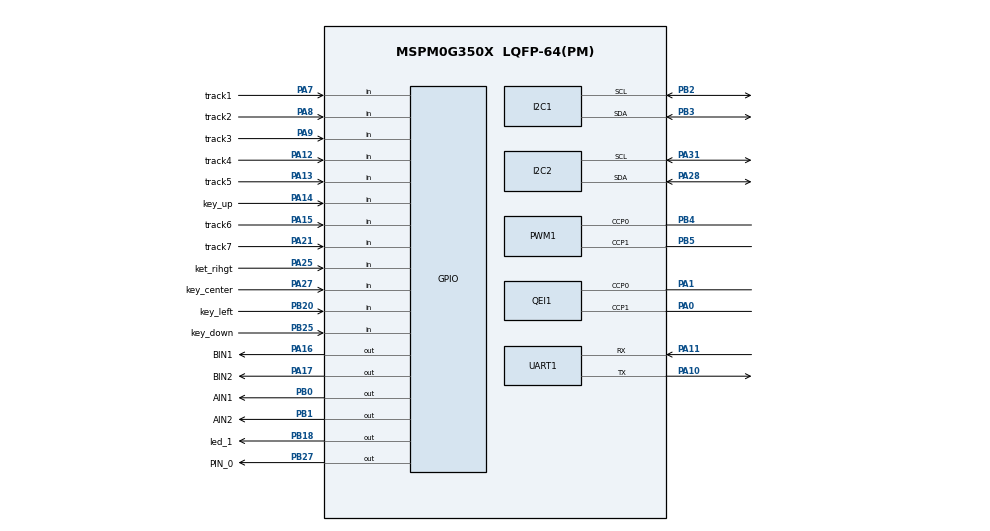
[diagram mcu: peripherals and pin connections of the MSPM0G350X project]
/**
 * @cliArgs --device "MSPM0G350X" --part "Default" --package "LQFP-64(PM)" --product "mspm0_sdk@2.04.00.06"
 * @versions {"tool":"1.23.1+4034"}
 */

/**
 * Import the modules used in this configuration.
 */
const GPIO    = scripting.addModule("/ti/driverlib/GPIO", {}, false);
const GPIO1   = GPIO.addInstance();
const GPIO2   = GPIO.addInstance();
const GPIO3   = GPIO.addInstance();
const GPIO4   = GPIO.addInstance();
const GPIO5   = GPIO.addInstance();
const I2C     = scripting.addModule("/ti/driverlib/I2C", {}, false);
const I2C1    = I2C.addInstance();
const I2C2    = I2C.addInstance();
const PWM     = scripting.addModule("/ti/driverlib/PWM", {}, false);
const PWM1    = PWM.addInstance();
const QEI     = scripting.addModule("/ti/driverlib/QEI", {}, false);
const QEI1    = QEI.addInstance();
const SYSCTL  = scripting.addModule("/ti/driverlib/SYSCTL");
const SYSTICK = scripting.addModule("/ti/driverlib/SYSTICK");
const TIMER   = scripting.addModule("/ti/driverlib/TIMER", {}, false);
const TIMER1  = TIMER.addInstance();
const TIMER2  = TIMER.addInstance();
const TIMER3  = TIMER.addInstance();
const UART    = scripting.addModule("/ti/driverlib/UART", {}, false);
const UART1   = UART.addInstance();

/**
 * Write custom configuration values to the imported modules.
 */
const divider9       = system.clockTree["UDIV"];
divider9.divideValue = 2;

const gate7  = system.clockTree["MFCLKGATE"];
gate7.enable = true;

const multiplier2         = system.clockTree["PLL_QDIV"];
multiplier2.multiplyValue = 4;

const mux4       = system.clockTree["EXHFMUX"];
mux4.inputSelect = "EXHFMUX_XTAL";

const mux8       = system.clockTree["HSCLKMUX"];
mux8.inputSelect = "HSCLKMUX_SYSPLL0";

const mux12       = system.clockTree["SYSPLLMUX"];
mux12.inputSelect = "zSYSPLLMUX_HFCLK";

const pinFunction4        = system.clockTree["HFXT"];
pinFunction4.enable       = true;
pinFunction4.inputFreq    = 40;
pinFunction4.HFXTStartup  = 10;
pinFunction4.HFCLKMonitor = true;

GPIO1.$name                              = "key_gpio";
GPIO1.associatedPins.create(5);
GPIO1.associatedPins[0].direction        = "INPUT";
GPIO1.associatedPins[0].internalResistor = "PULL_DOWN";
GPIO1.associatedPins[0].assignedPort     = "PORTA";
GPIO1.associatedPins[0].$name            = "key_center";
GPIO1.associatedPins[0].assignedPin      = "27";
GPIO1.associatedPins[0].pin.$assign      = "PA27";
GPIO1.associatedPins[1].$name            = "ket_rihgt";
GPIO1.associatedPins[1].direction        = "INPUT";
GPIO1.associatedPins[1].internalResistor = "PULL_DOWN";
GPIO1.associatedPins[1].assignedPort     = "PORTA";
GPIO1.associatedPins[1].assignedPin      = "25";
GPIO1.associatedPins[1].pin.$assign      = "PA25";
GPIO1.associatedPins[2].$name            = "key_left";
GPIO1.associatedPins[2].direction        = "INPUT";
GPIO1.associatedPins[2].internalResistor = "PULL_DOWN";
GPIO1.associatedPins[2].assignedPort     = "PORTB";
GPIO1.associatedPins[2].assignedPin      = "20";
GPIO1.associatedPins[2].pin.$assign      = "PB20";
GPIO1.associatedPins[3].$name            = "key_up";
GPIO1.associatedPins[3].direction        = "INPUT";
GPIO1.associatedPins[3].internalResistor = "PULL_DOWN";
GPIO1.associatedPins[3].assignedPort     = "PORTA";
GPIO1.associatedPins[3].assignedPin      = "14";
GPIO1.associatedPins[3].pin.$assign      = "PA14";
GPIO1.associatedPins[4].$name            = "key_down";
GPIO1.associatedPins[4].direction        = "INPUT";
GPIO1.associatedPins[4].assignedPort     = "PORTB";
GPIO1.associatedPins[4].assignedPin      = "25";
GPIO1.associatedPins[4].internalResistor = "PULL_DOWN";
GPIO1.associatedPins[4].pin.$assign      = "PB25";

const Board = scripting.addModule("/ti/driverlib/Board", {}, false);

GPIO2.$name                         = "buzzer_gpio";
GPIO2.port                          = "PORTB";
GPIO2.associatedPins[0].$name       = "PIN_0";
GPIO2.associatedPins[0].assignedPin = "27";
GPIO2.associatedPins[0].pin.$assign = "PB27";

GPIO3.$name                         = "debug_led_gpio";
GPIO3.port                          = "PORTB";
GPIO3.associatedPins[0].$name       = "led_1";
GPIO3.associatedPins[0].assignedPin = "18";
GPIO3.associatedPins[0].pin.$assign = "PB18";

GPIO4.$name                          = "motor_dir";
GPIO4.associatedPins.create(4);
GPIO4.associatedPins[0].$name        = "AIN1";
GPIO4.associatedPins[0].initialValue = "SET";
GPIO4.associatedPins[0].pin.$assign  = "PB0";
GPIO4.associatedPins[1].$name        = "AIN2";
GPIO4.associatedPins[1].initialValue = "SET";
GPIO4.associatedPins[1].pin.$assign  = "PB1";
GPIO4.associatedPins[2].$name        = "BIN1";
GPIO4.associatedPins[2].initialValue = "SET";
GPIO4.associatedPins[2].pin.$assign  = "PA16";
GPIO4.associatedPins[3].$name        = "BIN2";
GPIO4.associatedPins[3].initialValue = "SET";
GPIO4.associatedPins[3].pin.$assign  = "PA17";

GPIO5.$name                              = "track_gpio";
GPIO5.port                               = "PORTA";
GPIO5.associatedPins.create(7);
GPIO5.associatedPins[0].$name            = "track1";
GPIO5.associatedPins[0].direction        = "INPUT";
GPIO5.associatedPins[0].internalResistor = "PULL_DOWN";
GPIO5.associatedPins[0].pin.$assign      = "PA7";
GPIO5.associatedPins[1].$name            = "track2";
GPIO5.associatedPins[1].direction        = "INPUT";
GPIO5.associatedPins[1].internalResistor = "PULL_DOWN";
GPIO5.associatedPins[1].pin.$assign      = "PA8";
GPIO5.associatedPins[2].$name            = "track3";
GPIO5.associatedPins[2].direction        = "INPUT";
GPIO5.associatedPins[2].internalResistor = "PULL_DOWN";
GPIO5.associatedPins[2].pin.$assign      = "PA9";
GPIO5.associatedPins[3].$name            = "track4";
GPIO5.associatedPins[3].direction        = "INPUT";
GPIO5.associatedPins[3].internalResistor = "PULL_DOWN";
GPIO5.associatedPins[3].pin.$assign      = "PA12";
GPIO5.associatedPins[4].$name            = "track5";
GPIO5.associatedPins[4].direction        = "INPUT";
GPIO5.associatedPins[4].internalResistor = "PULL_DOWN";
GPIO5.associatedPins[4].pin.$assign      = "PA13";
GPIO5.associatedPins[5].$name            = "track6";
GPIO5.associatedPins[5].direction        = "INPUT";
GPIO5.associatedPins[5].internalResistor = "PULL_DOWN";
GPIO5.associatedPins[5].pin.$assign      = "PA15";
GPIO5.associatedPins[6].$name            = "track7";
GPIO5.associatedPins[6].direction        = "INPUT";
GPIO5.associatedPins[6].internalResistor = "PULL_DOWN";
GPIO5.associatedPins[6].pin.$assign      = "PA21";

I2C1.$name                             = "OLED";
I2C1.basicEnableController             = true;
I2C1.peripheral.$assign                = "I2C1";
I2C1.peripheral.sdaPin.$assign         = "PB3";
I2C1.peripheral.sclPin.$assign         = "PB2";
I2C1.sdaPinConfig.$name                = "ti_driverlib_gpio_GPIOPinGeneric0";
I2C1.sdaPinConfig.hideOutputInversion  = scripting.forceWrite(false);
I2C1.sdaPinConfig.onlyInternalResistor = scripting.forceWrite(false);
I2C1.sdaPinConfig.passedPeripheralType = scripting.forceWrite("Digital");
I2C1.sclPinConfig.$name                = "ti_driverlib_gpio_GPIOPinGeneric1";
I2C1.sclPinConfig.hideOutputInversion  = scripting.forceWrite(false);
I2C1.sclPinConfig.onlyInternalResistor = scripting.forceWrite(false);
I2C1.sclPinConfig.passedPeripheralType = scripting.forceWrite("Digital");

I2C2.$name                             = "imu660rb";
I2C2.basicEnableController             = true;
I2C2.basicControllerStandardBusSpeed   = "Fast";
I2C2.peripheral.$assign                = "I2C0";
I2C2.peripheral.sdaPin.$assign         = "PA28";
I2C2.peripheral.sclPin.$assign         = "PA31";
I2C2.sdaPinConfig.hideOutputInversion  = scripting.forceWrite(false);
I2C2.sdaPinConfig.onlyInternalResistor = scripting.forceWrite(false);
I2C2.sdaPinConfig.passedPeripheralType = scripting.forceWrite("Digital");
I2C2.sdaPinConfig.$name                = "ti_driverlib_gpio_GPIOPinGeneric4";
I2C2.sclPinConfig.hideOutputInversion  = scripting.forceWrite(false);
I2C2.sclPinConfig.onlyInternalResistor = scripting.forceWrite(false);
I2C2.sclPinConfig.passedPeripheralType = scripting.forceWrite("Digital");
I2C2.sclPinConfig.$name                = "ti_driverlib_gpio_GPIOPinGeneric5";

PWM1.clockDivider                       = 8;
PWM1.timerStartTimer                    = true;
PWM1.timerCount                         = 10001;
PWM1.$name                              = "motor_pwm";
PWM1.peripheral.$assign                 = "TIMA1";
PWM1.peripheral.ccp0Pin.$assign         = "PB4";
PWM1.peripheral.ccp1Pin.$assign         = "PB5";
PWM1.PWM_CHANNEL_0.$name                = "ti_driverlib_pwm_PWMTimerCC0";
PWM1.PWM_CHANNEL_0.invert               = true;
PWM1.PWM_CHANNEL_1.$name                = "ti_driverlib_pwm_PWMTimerCC1";
PWM1.PWM_CHANNEL_1.invert               = true;
PWM1.ccp0PinConfig.direction            = scripting.forceWrite("OUTPUT");
PWM1.ccp0PinConfig.hideOutputInversion  = scripting.forceWrite(false);
PWM1.ccp0PinConfig.onlyInternalResistor = scripting.forceWrite(false);
PWM1.ccp0PinConfig.passedPeripheralType = scripting.forceWrite("Digital");
PWM1.ccp0PinConfig.$name                = "ti_driverlib_gpio_GPIOPinGeneric6";
PWM1.ccp1PinConfig.direction            = scripting.forceWrite("OUTPUT");
PWM1.ccp1PinConfig.hideOutputInversion  = scripting.forceWrite(false);
PWM1.ccp1PinConfig.onlyInternalResistor = scripting.forceWrite(false);
PWM1.ccp1PinConfig.passedPeripheralType = scripting.forceWrite("Digital");
PWM1.ccp1PinConfig.$name                = "ti_driverlib_gpio_GPIOPinGeneric7";

QEI1.$name                              = "encoder_qei";
QEI1.clockDivider                       = 8;
QEI1.timerStartTimer                    = true;
QEI1.peripheral.$assign                 = "TIMG8";
QEI1.peripheral.ccp0Pin.$assign         = "PA1";
QEI1.peripheral.ccp1Pin.$assign         = "PA0";
QEI1.ccp0PinConfig.hideOutputInversion  = scripting.forceWrite(false);
QEI1.ccp0PinConfig.onlyInternalResistor = scripting.forceWrite(false);
QEI1.ccp0PinConfig.passedPeripheralType = scripting.forceWrite("Digital");
QEI1.ccp0PinConfig.$name                = "ti_driverlib_gpio_GPIOPinGeneric8";
QEI1.ccp1PinConfig.hideOutputInversion  = scripting.forceWrite(false);
QEI1.ccp1PinConfig.onlyInternalResistor = scripting.forceWrite(false);
QEI1.ccp1PinConfig.passedPeripheralType = scripting.forceWrite("Digital");
QEI1.ccp1PinConfig.$name                = "ti_driverlib_gpio_GPIOPinGeneric9";

SYSCTL.forceDefaultClkConfig = true;
SYSCTL.clockTreeEn           = true;

SYSTICK.interruptEnable   = true;
SYSTICK.interruptPriority = "0";
SYSTICK.periodEnable      = true;
SYSTICK.period            = 80000;
SYSTICK.systickEnable     = true;

TIMER1.$name             = "IMU_TIMER";
TIMER1.timerClkDiv       = 8;
TIMER1.timerMode         = "PERIODIC";
TIMER1.timerClkPrescale  = 100;
TIMER1.timerStartTimer   = true;
TIMER1.interrupts        = ["ZERO"];
TIMER1.interruptPriority = "1";
TIMER1.timerPeriod       = "5ms";

TIMER2.$name             = "ENCODER_TIMER";
TIMER2.timerClkDiv       = 8;
TIMER2.timerClkPrescale  = 100;
TIMER2.timerMode         = "PERIODIC";
TIMER2.timerStartTimer   = true;
TIMER2.interrupts        = ["ZERO"];
TIMER2.timerPeriod       = "5ms";
TIMER2.interruptPriority = "1";

TIMER3.$name             = "PID_TIMER";
TIMER3.timerClkDiv       = 8;
TIMER3.timerClkPrescale  = 100;
TIMER3.timerMode         = "PERIODIC";
TIMER3.timerStartTimer   = true;
TIMER3.interrupts        = ["ZERO"];
TIMER3.interruptPriority = "2";
TIMER3.timerPeriod       = "50ms";

UART1.$name                            = "Debug_UART";
UART1.targetBaudRate                   = 115200;
UART1.uartClkSrc                       = "MFCLK";
UART1.enabledInterrupts                = ["RX"];
UART1.interruptPriority                = "3";
UART1.peripheral.$assign               = "UART0";
UART1.peripheral.rxPin.$assign         = "PA11";
UART1.peripheral.txPin.$assign         = "PA10";
UART1.txPinConfig.direction            = scripting.forceWrite("OUTPUT");
UART1.txPinConfig.hideOutputInversion  = scripting.forceWrite(false);
UART1.txPinConfig.onlyInternalResistor = scripting.forceWrite(false);
UART1.txPinConfig.passedPeripheralType = scripting.forceWrite("Digital");
UART1.txPinConfig.$name                = "ti_driverlib_gpio_GPIOPinGeneric2";
UART1.rxPinConfig.hideOutputInversion  = scripting.forceWrite(false);
UART1.rxPinConfig.onlyInternalResistor = scripting.forceWrite(false);
UART1.rxPinConfig.passedPeripheralType = scripting.forceWrite("Digital");
UART1.rxPinConfig.$name                = "ti_driverlib_gpio_GPIOPinGeneric3";

/**
 * Pinmux solution for unlocked pins/peripherals. This ensures that minor changes to the automatic solver in a future
 * version of the tool will not impact the pinmux you originally saw.  These lines can be completely deleted in order to
 * re-solve from scratch.
 */
pinFunction4.peripheral.$suggestSolution           = "SYSCTL";
pinFunction4.peripheral.hfxInPin.$suggestSolution  = "PA5";
pinFunction4.peripheral.hfxOutPin.$suggestSolution = "PA6";
Board.peripheral.$suggestSolution                  = "DEBUGSS";
Board.peripheral.swclkPin.$suggestSolution         = "PA20";
Board.peripheral.swdioPin.$suggestSolution         = "PA19";
TIMER1.peripheral.$suggestSolution                 = "TIMG6";
TIMER2.peripheral.$suggestSolution                 = "TIMG0";
TIMER3.peripheral.$suggestSolution                 = "TIMA0";
